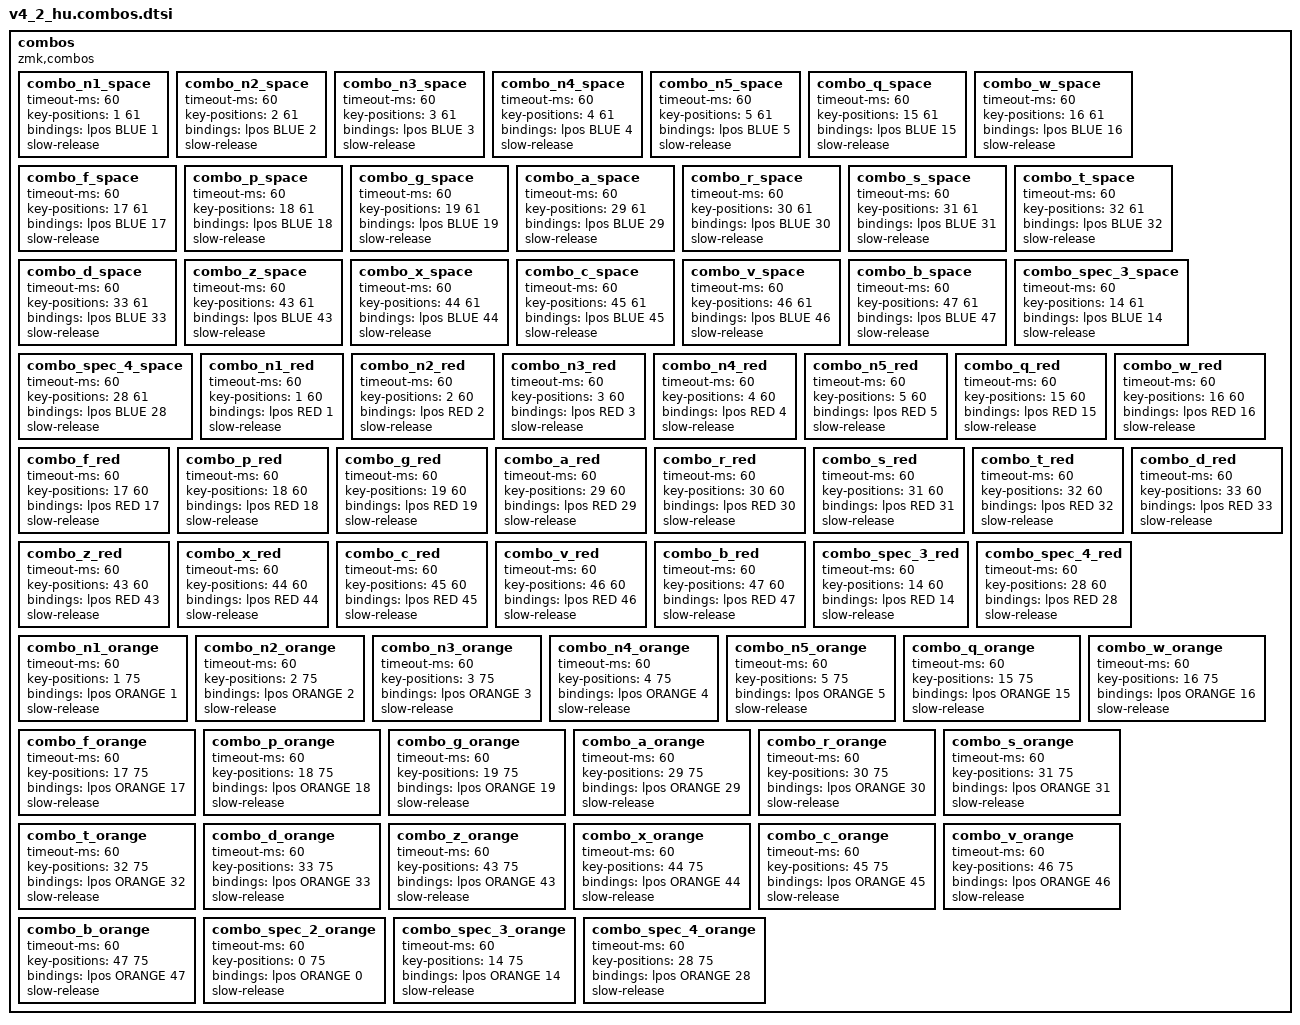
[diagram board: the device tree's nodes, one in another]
/*
 * The combos of the HU MonoTypist, generated by tools/gen-keymap.mjs from layout/hu.json.
 * Do not edit this file: change layout/hu.json and run "node tools/gen-keymap.mjs".
 */

combos {
    compatible = "zmk,combos";

    combo_n1_space { timeout-ms = <60>; key-positions = <1 61>; bindings = <&lpos BLUE 1>; slow-release; };
    combo_n2_space { timeout-ms = <60>; key-positions = <2 61>; bindings = <&lpos BLUE 2>; slow-release; };
    combo_n3_space { timeout-ms = <60>; key-positions = <3 61>; bindings = <&lpos BLUE 3>; slow-release; };
    combo_n4_space { timeout-ms = <60>; key-positions = <4 61>; bindings = <&lpos BLUE 4>; slow-release; };
    combo_n5_space { timeout-ms = <60>; key-positions = <5 61>; bindings = <&lpos BLUE 5>; slow-release; };
    combo_q_space { timeout-ms = <60>; key-positions = <15 61>; bindings = <&lpos BLUE 15>; slow-release; };
    combo_w_space { timeout-ms = <60>; key-positions = <16 61>; bindings = <&lpos BLUE 16>; slow-release; };
    combo_f_space { timeout-ms = <60>; key-positions = <17 61>; bindings = <&lpos BLUE 17>; slow-release; };
    combo_p_space { timeout-ms = <60>; key-positions = <18 61>; bindings = <&lpos BLUE 18>; slow-release; };
    combo_g_space { timeout-ms = <60>; key-positions = <19 61>; bindings = <&lpos BLUE 19>; slow-release; };
    combo_a_space { timeout-ms = <60>; key-positions = <29 61>; bindings = <&lpos BLUE 29>; slow-release; };
    combo_r_space { timeout-ms = <60>; key-positions = <30 61>; bindings = <&lpos BLUE 30>; slow-release; };
    combo_s_space { timeout-ms = <60>; key-positions = <31 61>; bindings = <&lpos BLUE 31>; slow-release; };
    combo_t_space { timeout-ms = <60>; key-positions = <32 61>; bindings = <&lpos BLUE 32>; slow-release; };
    combo_d_space { timeout-ms = <60>; key-positions = <33 61>; bindings = <&lpos BLUE 33>; slow-release; };
    combo_z_space { timeout-ms = <60>; key-positions = <43 61>; bindings = <&lpos BLUE 43>; slow-release; };
    combo_x_space { timeout-ms = <60>; key-positions = <44 61>; bindings = <&lpos BLUE 44>; slow-release; };
    combo_c_space { timeout-ms = <60>; key-positions = <45 61>; bindings = <&lpos BLUE 45>; slow-release; };
    combo_v_space { timeout-ms = <60>; key-positions = <46 61>; bindings = <&lpos BLUE 46>; slow-release; };
    combo_b_space { timeout-ms = <60>; key-positions = <47 61>; bindings = <&lpos BLUE 47>; slow-release; };
    combo_spec_3_space { timeout-ms = <60>; key-positions = <14 61>; bindings = <&lpos BLUE 14>; slow-release; };
    combo_spec_4_space { timeout-ms = <60>; key-positions = <28 61>; bindings = <&lpos BLUE 28>; slow-release; };
    combo_n1_red { timeout-ms = <60>; key-positions = <1 60>; bindings = <&lpos RED 1>; slow-release; };
    combo_n2_red { timeout-ms = <60>; key-positions = <2 60>; bindings = <&lpos RED 2>; slow-release; };
    combo_n3_red { timeout-ms = <60>; key-positions = <3 60>; bindings = <&lpos RED 3>; slow-release; };
    combo_n4_red { timeout-ms = <60>; key-positions = <4 60>; bindings = <&lpos RED 4>; slow-release; };
    combo_n5_red { timeout-ms = <60>; key-positions = <5 60>; bindings = <&lpos RED 5>; slow-release; };
    combo_q_red { timeout-ms = <60>; key-positions = <15 60>; bindings = <&lpos RED 15>; slow-release; };
    combo_w_red { timeout-ms = <60>; key-positions = <16 60>; bindings = <&lpos RED 16>; slow-release; };
    combo_f_red { timeout-ms = <60>; key-positions = <17 60>; bindings = <&lpos RED 17>; slow-release; };
    combo_p_red { timeout-ms = <60>; key-positions = <18 60>; bindings = <&lpos RED 18>; slow-release; };
    combo_g_red { timeout-ms = <60>; key-positions = <19 60>; bindings = <&lpos RED 19>; slow-release; };
    combo_a_red { timeout-ms = <60>; key-positions = <29 60>; bindings = <&lpos RED 29>; slow-release; };
    combo_r_red { timeout-ms = <60>; key-positions = <30 60>; bindings = <&lpos RED 30>; slow-release; };
    combo_s_red { timeout-ms = <60>; key-positions = <31 60>; bindings = <&lpos RED 31>; slow-release; };
    combo_t_red { timeout-ms = <60>; key-positions = <32 60>; bindings = <&lpos RED 32>; slow-release; };
    combo_d_red { timeout-ms = <60>; key-positions = <33 60>; bindings = <&lpos RED 33>; slow-release; };
    combo_z_red { timeout-ms = <60>; key-positions = <43 60>; bindings = <&lpos RED 43>; slow-release; };
    combo_x_red { timeout-ms = <60>; key-positions = <44 60>; bindings = <&lpos RED 44>; slow-release; };
    combo_c_red { timeout-ms = <60>; key-positions = <45 60>; bindings = <&lpos RED 45>; slow-release; };
    combo_v_red { timeout-ms = <60>; key-positions = <46 60>; bindings = <&lpos RED 46>; slow-release; };
    combo_b_red { timeout-ms = <60>; key-positions = <47 60>; bindings = <&lpos RED 47>; slow-release; };
    combo_spec_3_red { timeout-ms = <60>; key-positions = <14 60>; bindings = <&lpos RED 14>; slow-release; };
    combo_spec_4_red { timeout-ms = <60>; key-positions = <28 60>; bindings = <&lpos RED 28>; slow-release; };
    combo_n1_orange { timeout-ms = <60>; key-positions = <1 75>; bindings = <&lpos ORANGE 1>; slow-release; };
    combo_n2_orange { timeout-ms = <60>; key-positions = <2 75>; bindings = <&lpos ORANGE 2>; slow-release; };
    combo_n3_orange { timeout-ms = <60>; key-positions = <3 75>; bindings = <&lpos ORANGE 3>; slow-release; };
    combo_n4_orange { timeout-ms = <60>; key-positions = <4 75>; bindings = <&lpos ORANGE 4>; slow-release; };
    combo_n5_orange { timeout-ms = <60>; key-positions = <5 75>; bindings = <&lpos ORANGE 5>; slow-release; };
    combo_q_orange { timeout-ms = <60>; key-positions = <15 75>; bindings = <&lpos ORANGE 15>; slow-release; };
    combo_w_orange { timeout-ms = <60>; key-positions = <16 75>; bindings = <&lpos ORANGE 16>; slow-release; };
    combo_f_orange { timeout-ms = <60>; key-positions = <17 75>; bindings = <&lpos ORANGE 17>; slow-release; };
    combo_p_orange { timeout-ms = <60>; key-positions = <18 75>; bindings = <&lpos ORANGE 18>; slow-release; };
    combo_g_orange { timeout-ms = <60>; key-positions = <19 75>; bindings = <&lpos ORANGE 19>; slow-release; };
    combo_a_orange { timeout-ms = <60>; key-positions = <29 75>; bindings = <&lpos ORANGE 29>; slow-release; };
    combo_r_orange { timeout-ms = <60>; key-positions = <30 75>; bindings = <&lpos ORANGE 30>; slow-release; };
    combo_s_orange { timeout-ms = <60>; key-positions = <31 75>; bindings = <&lpos ORANGE 31>; slow-release; };
    combo_t_orange { timeout-ms = <60>; key-positions = <32 75>; bindings = <&lpos ORANGE 32>; slow-release; };
    combo_d_orange { timeout-ms = <60>; key-positions = <33 75>; bindings = <&lpos ORANGE 33>; slow-release; };
    combo_z_orange { timeout-ms = <60>; key-positions = <43 75>; bindings = <&lpos ORANGE 43>; slow-release; };
    combo_x_orange { timeout-ms = <60>; key-positions = <44 75>; bindings = <&lpos ORANGE 44>; slow-release; };
    combo_c_orange { timeout-ms = <60>; key-positions = <45 75>; bindings = <&lpos ORANGE 45>; slow-release; };
    combo_v_orange { timeout-ms = <60>; key-positions = <46 75>; bindings = <&lpos ORANGE 46>; slow-release; };
    combo_b_orange { timeout-ms = <60>; key-positions = <47 75>; bindings = <&lpos ORANGE 47>; slow-release; };
    combo_spec_2_orange { timeout-ms = <60>; key-positions = <0 75>; bindings = <&lpos ORANGE 0>; slow-release; };
    combo_spec_3_orange { timeout-ms = <60>; key-positions = <14 75>; bindings = <&lpos ORANGE 14>; slow-release; };
    combo_spec_4_orange { timeout-ms = <60>; key-positions = <28 75>; bindings = <&lpos ORANGE 28>; slow-release; };
};
